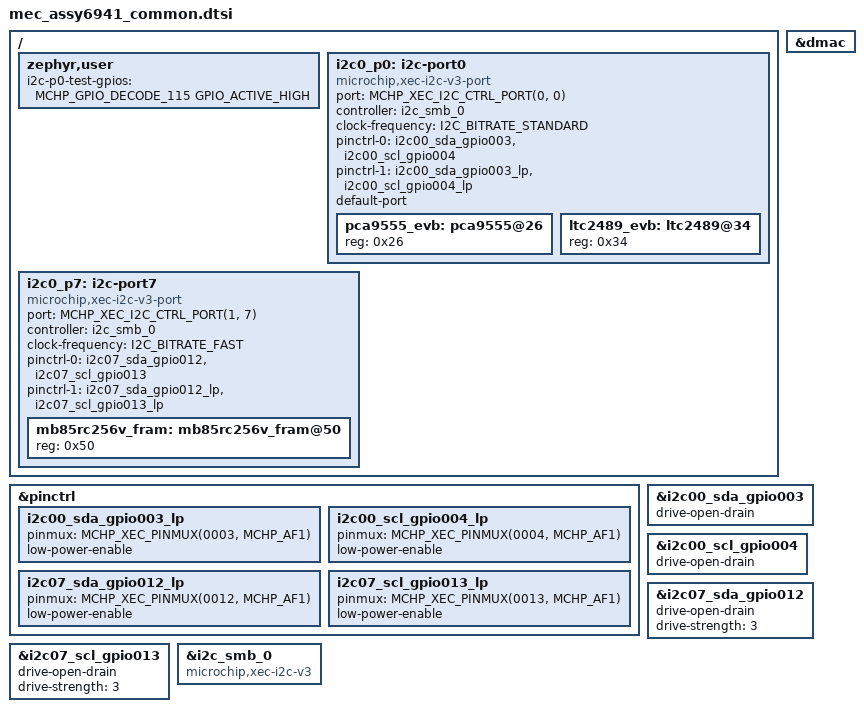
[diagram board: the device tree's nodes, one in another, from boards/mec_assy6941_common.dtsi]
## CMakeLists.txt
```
# Copyright (c) 2022 Microchip Technology Inc.
#
# SPDX-License-Identifier: Apache-2.0
#
cmake_minimum_required(VERSION 3.20.0)

find_package(Zephyr REQUIRED HINTS $ENV{ZEPHYR_BASE})
project(sample_boards_microchip_xec_i2c_v3)

file(GLOB app_sources src/*.c)
target_sources(app PRIVATE ${app_sources})
```

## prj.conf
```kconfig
# Enable config log
CONFIG_STDOUT_CONSOLE=y
CONFIG_LOG=y

CONFIG_DMA=y
CONFIG_I2C=y
```

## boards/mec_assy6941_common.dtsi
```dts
/*
 * Copyright (c) 2026 Microchip Technology Inc.
 *
 * SPDX-License-Identifier: Apache-2.0
 */

#include <zephyr/dt-bindings/gpio/microchip-xec-gpio.h>
#include <zephyr/dt-bindings/dma/mchp-xec-dmac.h>
#include <zephyr/dt-bindings/i2c/i2c.h>
#include <zephyr/dt-bindings/i2c/mchp-xec-i2c.h>

&dmac {
	status = "okay";
};

&pinctrl {
	i2c00_sda_gpio003_lp: i2c00_sda_gpio003_lp {
		pinmux = <MCHP_XEC_PINMUX(0003, MCHP_AF1)>;
		low-power-enable;
	};

	i2c00_scl_gpio004_lp: i2c00_scl_gpio004_lp {
		pinmux = <MCHP_XEC_PINMUX(0004, MCHP_AF1)>;
		low-power-enable;
	};

	i2c07_sda_gpio012_lp: i2c07_sda_gpio012_lp {
		pinmux = <MCHP_XEC_PINMUX(0012, MCHP_AF1)>;
		low-power-enable;
	};

	i2c07_scl_gpio013_lp: i2c07_scl_gpio013_lp {
		pinmux = <MCHP_XEC_PINMUX(0013, MCHP_AF1)>;
		low-power-enable;
	};
};

/* Port 0 pins */
&i2c00_sda_gpio003 {
	drive-open-drain;
};

&i2c00_scl_gpio004 {
	drive-open-drain;
};

/* Port 7 pins */
&i2c07_sda_gpio012 {
	drive-open-drain;
	drive-strength = <3>;
};

&i2c07_scl_gpio013 {
	drive-open-drain;
	drive-strength = <3>;
};

&i2c_smb_0 {
	compatible = "microchip,xec-i2c-v3";
	status = "okay";
	#address-cells = <1>;
	#size-cells = <0>;
};

/ {
	zephyr,user {
		i2c-p0-test-gpios = <MCHP_GPIO_DECODE_115 GPIO_ACTIVE_HIGH>;
	};

	/* Port 0 (default port) on I2C Controller 0 */
	i2c0_p0: i2c-port0 {
		compatible = "microchip,xec-i2c-v3-port";
		#address-cells = <1>;
		#size-cells = <0>;
		port = <MCHP_XEC_I2C_CTRL_PORT(0, 0)>;
		controller = <&i2c_smb_0>;
		clock-frequency = <I2C_BITRATE_STANDARD>;
		pinctrl-0 = <&i2c00_sda_gpio003 &i2c00_scl_gpio004>;
		pinctrl-1 = <&i2c00_sda_gpio003_lp &i2c00_scl_gpio004_lp>;
		pinctrl-names = "default", "sleep";
		default-port;
		status = "okay";

		pca9555_evb: pca9555@26 {
			reg = <0x26>;
			status = "okay";
		};

		ltc2489_evb: ltc2489@34 {
			reg = <0x34>;
			status = "okay";
		};
	};

	/* Port 7 on I2C controller 0 */
	i2c0_p7: i2c-port7 {
		compatible = "microchip,xec-i2c-v3-port";
		#address-cells = <1>;
		#size-cells = <0>;
		port = <MCHP_XEC_I2C_CTRL_PORT(1, 7)>;
		controller = <&i2c_smb_0>;
		clock-frequency = <I2C_BITRATE_FAST>;
		pinctrl-0 = <&i2c07_sda_gpio012 &i2c07_scl_gpio013>;
		pinctrl-1 = <&i2c07_sda_gpio012_lp &i2c07_scl_gpio013_lp>;
		pinctrl-names = "default", "sleep";
		status = "okay";

		mb85rc256v_fram: mb85rc256v_fram@50 {
			reg = <0x50>;
			status = "okay";
		};
	};
};
```

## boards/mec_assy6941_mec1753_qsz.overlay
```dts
/*
 * Copyright (c) 2026 Microchip Technology Inc.
 *
 * SPDX-License-Identifier: Apache-2.0
 */

#include "mec_assy6941_common.dtsi"
```

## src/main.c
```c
/*
 * Copyright (c) 2026 Microchip Technology Inc.
 *
 * SPDX-License-Identifier: Apache-2.0
 */

#include <soc.h>
#include <string.h>
#include <zephyr/kernel.h>
#include <zephyr/device.h>
#include <zephyr/drivers/i2c.h>
#include <zephyr/dt-bindings/i2c/i2c.h>
#include <zephyr/dt-bindings/i2c/mchp-xec-i2c.h>

#include <zephyr/logging/log.h>
#include <zephyr/logging/log_ctrl.h>
LOG_MODULE_REGISTER(app, CONFIG_LOG_DEFAULT_LEVEL);

#define PCA9555_CMD_PORT0_IN  0
#define PCA9555_CMD_PORT1_IN  1u
#define PCA9555_CMD_PORT0_OUT 2u
#define PCA9555_CMD_PORT1_OUT 3u
#define PCA9555_CMD_PORT0_POL 4u
#define PCA9555_CMD_PORT1_POL 5u
#define PCA9555_CMD_PORT0_CFG 6u
#define PCA9555_CMD_PORT1_CFG 7u

#define LTC2489_ADC_CONV_TIME_MS 150
#define LTC2489_ADC_READ_RETRIES 10

#define ZEPHYR_USER_NODE DT_PATH(zephyr_user)

#define I2C_SMB_GET_DEV(nid) DEVICE_DT_GET(nid),

#define NODE_PCA9555 DT_NODELABEL(pca9555_evb)
#define NODE_LTC2489 DT_NODELABEL(ltc2489_evb)
#define NODE_FRAM    DT_NODELABEL(mb85rc256v_fram)

const struct i2c_dt_spec pca9555_spec = I2C_DT_SPEC_GET(NODE_PCA9555);
const struct i2c_dt_spec ltc2489_spec = I2C_DT_SPEC_GET(NODE_LTC2489);
const struct i2c_dt_spec mb_fram_spec = I2C_DT_SPEC_GET(NODE_FRAM);

/* Microchip byte-mode I2C driver supporting port switching */
static const struct device *i2c_smb_bm_ctrls[] = {
	DT_FOREACH_STATUS_OKAY(microchip_xec_i2c_v3, I2C_SMB_GET_DEV)};

#define I2C_MAX_MSGS    8
#define I2C_TX_BUF_SIZE 256
#define I2C_RX_BUF_SIZE 256

static struct i2c_msg msgs[I2C_MAX_MSGS];
static uint8_t i2c_tx_buf[I2C_TX_BUF_SIZE];
static uint8_t i2c_rx_buf[I2C_RX_BUF_SIZE];

static void init_test_buffers(void)
{
	memset((void *)msgs, 0, sizeof(msgs));
	memset(i2c_tx_buf, 0x55, I2C_TX_BUF_SIZE);
	memset(i2c_rx_buf, 0xAA, I2C_RX_BUF_SIZE);
}

static int check_i2c_hw_ready(const struct i2c_dt_spec *dts)
{
	if (dts == NULL) {
		return -EINVAL;
	}

	if (device_is_ready(dts->bus) == false) {
		LOG_ERR("Device %s is not ready", dts->bus->name);
		return -ENOTSUP;
	}

	return 0;
}

int main(void)
{
	int rc = 0;

	init_test_buffers();

	for (size_t n = 0; n < ARRAY_SIZE(i2c_smb_bm_ctrls); n++) {
		const struct device *i2c_cr_dev = i2c_smb_bm_ctrls[n];

		if (device_is_ready(i2c_cr_dev)) {
			LOG_ERR("I2C controller %s is not ready", i2c_cr_dev->name);
			rc = -ENOSYS;
		}
	}

	if (rc != 0) {
		goto app_end;
	}

	rc = check_i2c_hw_ready(&pca9555_spec);
	if (rc != 0) {
		goto app_end;
	}

	rc = check_i2c_hw_ready(&ltc2489_spec);
	if (rc != 0) {
		goto app_end;
	}

	rc = check_i2c_hw_ready(&mb_fram_spec);
	if (rc != 0) {
		goto app_end;
	}


app_end:
	LOG_INF("App End");

	return 0;
}
```
